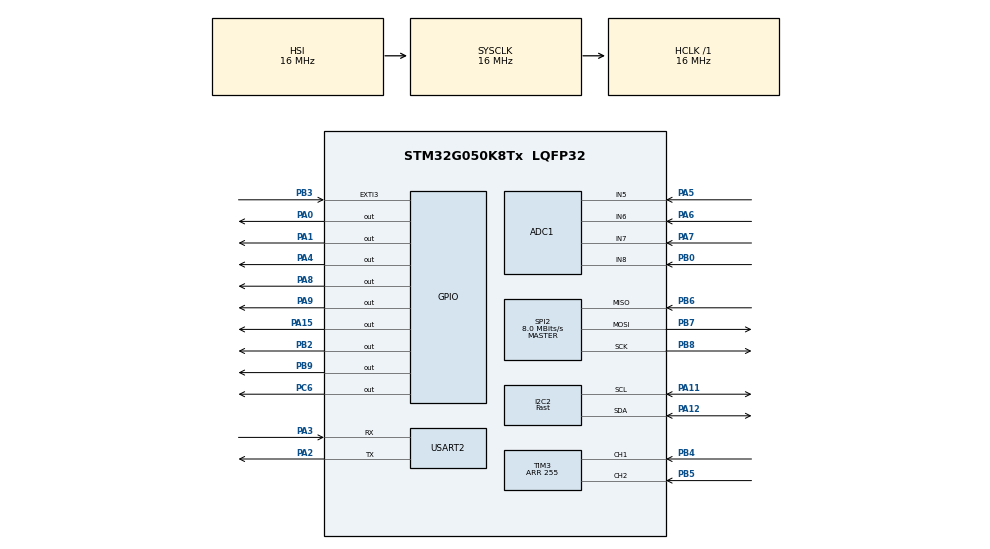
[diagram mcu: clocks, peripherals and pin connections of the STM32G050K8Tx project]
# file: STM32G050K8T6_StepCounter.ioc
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ADC1.Channel-0\#ChannelRegularConversion=ADC_CHANNEL_5
ADC1.Channel-1\#ChannelRegularConversion=ADC_CHANNEL_6
ADC1.Channel-2\#ChannelRegularConversion=ADC_CHANNEL_7
ADC1.Channel-3\#ChannelRegularConversion=ADC_CHANNEL_8
ADC1.ContinuousConvMode=ENABLE
ADC1.EOCSelection=ADC_EOC_SEQ_CONV
ADC1.NbrOfConversion=4
ADC1.NbrOfConversionFlag=1
ADC1.Rank-0\#ChannelRegularConversion=1
ADC1.Rank-1\#ChannelRegularConversion=2
ADC1.Rank-2\#ChannelRegularConversion=3
ADC1.Rank-3\#ChannelRegularConversion=4
ADC1.SamplingTime-0\#ChannelRegularConversion=ADC_SAMPLINGTIME_COMMON_1
ADC1.SamplingTime-1\#ChannelRegularConversion=ADC_SAMPLINGTIME_COMMON_1
ADC1.SamplingTime-2\#ChannelRegularConversion=ADC_SAMPLINGTIME_COMMON_1
ADC1.SamplingTime-3\#ChannelRegularConversion=ADC_SAMPLINGTIME_COMMON_1
ADC1.SelectedChannel=ADC_CHANNEL_5|ADC_CHANNEL_6|ADC_CHANNEL_7|ADC_CHANNEL_8
ADC1.master=1
Dma.ADC1.0.Direction=DMA_PERIPH_TO_MEMORY
Dma.ADC1.0.EventEnable=DISABLE
Dma.ADC1.0.Instance=DMA1_Channel1
Dma.ADC1.0.MemDataAlignment=DMA_MDATAALIGN_HALFWORD
Dma.ADC1.0.MemInc=DMA_MINC_ENABLE
Dma.ADC1.0.Mode=DMA_CIRCULAR
Dma.ADC1.0.PeriphDataAlignment=DMA_PDATAALIGN_HALFWORD
Dma.ADC1.0.PeriphInc=DMA_PINC_DISABLE
Dma.ADC1.0.Polarity=HAL_DMAMUX_REQ_GEN_RISING
Dma.ADC1.0.Priority=DMA_PRIORITY_LOW
Dma.ADC1.0.RequestNumber=1
Dma.ADC1.0.SignalID=NONE
Dma.ADC1.0.SyncEnable=DISABLE
Dma.ADC1.0.SyncPolarity=HAL_DMAMUX_SYNC_NO_EVENT
Dma.ADC1.0.SyncRequestNumber=1
Dma.ADC1.0.SyncSignalID=NONE
Dma.Request0=ADC1
I2C2.I2C_Speed_Mode=I2C_Fast
I2C2.Timing=0x00300617
Mcu.Family=STM32G0
Mcu.Name=STM32G050K8Tx
Mcu.Package=LQFP32
NVIC.DMA1_Channel1_IRQn=true\:0\:0\:false\:false\:true\:false\:true\:true
NVIC.TIM3_IRQn=true\:0\:0\:false\:false\:true\:true\:true\:true
PA0.Signal=GPIO_Output
PA1.Signal=GPIO_Output
PA11\ [PA9].Mode=I2C
PA11\ [PA9].Signal=I2C2_SCL
PA12\ [PA10].Mode=I2C
PA12\ [PA10].Signal=I2C2_SDA
PA13.Mode=Serial_Wire
PA13.Signal=SYS_SWDIO
PA14-BOOT0.Mode=Serial_Wire
PA14-BOOT0.Signal=SYS_SWCLK
PA15.Signal=GPIO_Output
PA2.Mode=Asynchronous
PA2.Signal=USART2_TX
PA3.Mode=Asynchronous
PA3.Signal=USART2_RX
PA4.Signal=GPIO_Output
PA5.Mode=IN5
PA5.Signal=ADC1_IN5
PA6.Mode=IN6
PA6.Signal=ADC1_IN6
PA7.Mode=IN7
PA7.Signal=ADC1_IN7
PA8.Signal=GPIO_Output
PA9.Signal=GPIO_Output
PB0.Mode=IN8
PB0.Signal=ADC1_IN8
PB2.Signal=GPIO_Output
PB3.Signal=GPXTI3
PB4.Signal=S_TIM3_CH1
PB5.Signal=S_TIM3_CH2
PB6.Mode=Full_Duplex_Master
PB6.Signal=SPI2_MISO
PB7.Mode=Full_Duplex_Master
PB7.Signal=SPI2_MOSI
PB8.Mode=Full_Duplex_Master
PB8.Signal=SPI2_SCK
PB9.Signal=GPIO_Output
PC6.Signal=GPIO_Output
ProjectManager.HeapSize=0x200
ProjectManager.StackSize=0x400
ProjectManager.TargetToolchain=STM32CubeIDE
RCC.AHBFreq_Value=16000000
RCC.CortexFreq_Value=16000000
RCC.EXTERNAL_CLOCK_VALUE=48000
RCC.HCLKFreq_Value=16000000
RCC.HSE_VALUE=8000000
RCC.HSI_VALUE=16000000
RCC.LSE_VALUE=32768
RCC.SYSCLKFreq_VALUE=16000000
RCC.VCOOutputFreq_Value=128000000
SH.S_TIM3_CH1.0=TIM3_CH1,Encoder_Interface
SH.S_TIM3_CH2.0=TIM3_CH2,Encoder_Interface
SPI2.CalculateBaudRate=8.0 MBits/s
SPI2.Direction=SPI_DIRECTION_2LINES
SPI2.Mode=SPI_MODE_MASTER
SPI2.VirtualType=VM_MASTER
TIM3.EncoderMode=TIM_ENCODERMODE_TI12
TIM3.IC1Polarity=TIM_ICPOLARITY_FALLING
TIM3.IC2Polarity=TIM_ICPOLARITY_FALLING
TIM3.Period=255
USART2.VirtualMode-Asynchronous=VM_ASYNC
VP_SYS_VS_DBSignals.Mode=DisableDeadBatterySignals
board=custom

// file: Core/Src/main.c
/* USER CODE BEGIN Header */
/**
  ******************************************************************************
  * @file           : main.c
  * @brief          : Main program body
  ******************************************************************************
  * @attention
  *
  * Copyright (c) 2025 STMicroelectronics.
  * All rights reserved.
  *
  * This software is licensed under terms that can be found in the LICENSE file
  * in the root directory of this software component.
  * If no LICENSE file comes with this software, it is provided AS-IS.
  *
  ******************************************************************************
  */
/* USER CODE END Header */
#include "main.h"

/* USER CODE BEGIN PD */
#define ADC_NUM_CONVERSIONS 3
#define ADC_RAW_TO_VOLTAGE 1.0071108127
#define VOLTAGE_INPUT 3.3
#define RESOLUTION 4096
#define g_BIAS_XY 1.65
#define g_BIAS_Z 1.8
#define SENSITIVITY 300
#define SELF_TEST_GPIO 4
#define SELF_TEST_MIN {-150, 150, 150}
#define SELF_TEST_TYP {-325, 325, 550}
#define SELF_TEST_MAX {-600, 600, 1000}
#define NUM_SAMPLES 100
#define G_TOLERANCE 0.05

float g_Bias[3] = {g_BIAS_XY, g_BIAS_XY, g_BIAS_Z};

/* USER CODE END PD */

ADC_HandleTypeDef hadc1;
DMA_HandleTypeDef hdma_adc1;

I2C_HandleTypeDef hi2c2;

SPI_HandleTypeDef hspi2;

TIM_HandleTypeDef htim3;

UART_HandleTypeDef huart2;

/* USER CODE BEGIN PV */
volatile uint16_t adcData[ADC_NUM_CONVERSIONS];
volatile float adxlVoltage[ADC_NUM_CONVERSIONS];
volatile float gData[ADC_NUM_CONVERSIONS];
volatile float VOLTAGE_ST[ADC_NUM_CONVERSIONS];
volatile float VOLTAGE_BUFFER_BEFORE[ADC_NUM_CONVERSIONS];
volatile float VOLTAGE_BUFFER_AFTER[ADC_NUM_CONVERSIONS];
const uint16_t SelfTestMin[ADC_NUM_CONVERSIONS] = SELF_TEST_MIN;
const uint16_t SelfTestTyp[ADC_NUM_CONVERSIONS] = SELF_TEST_TYP;
const uint16_t SelfTestMax[ADC_NUM_CONVERSIONS] = SELF_TEST_MAX;
volatile uint8_t CONVERSION = 0;
uint8_t pass = 0;
volatile uint8_t SELF_TEST = 0;
/* USER CODE END PV */

void SystemClock_Config(void);
static void MX_GPIO_Init(void);
static void MX_DMA_Init(void);
static void MX_ADC1_Init(void);
static void MX_I2C2_Init(void);
static void MX_SPI2_Init(void);
static void MX_TIM3_Init(void);
static void MX_USART2_UART_Init(void);

/* USER CODE BEGIN 0 */
void HAL_ADC_ConvCpltCallback(ADC_HandleTypeDef *hadc){
	CONVERSION = 1;
}

void Calculate_g(void){
	for(int i = 0; i < ADC_NUM_CONVERSIONS; i++){
	  adxlVoltage[i] = adcData[i] * VOLTAGE_INPUT/RESOLUTION * 1000;
	  gData[i] = (adxlVoltage[i] - g_Bias[i])/SENSITIVITY;
	}
}

void ToggleLED_ST(void){
	 HAL_GPIO_TogglePin(GPIOC, GPIO_PIN_6);
	 SELF_TEST = !SELF_TEST;                   // Toggle self-test flag
	 HAL_Delay(500);
}

void Perform_Self_Test(void){
	self_test_finished = false;
	//screen1();
	ToggleLED_ST();

	if(SELF_TEST) {
	  for(int i = 0; i < ADC_NUM_CONVERSIONS; i++) {
		  VOLTAGE_BUFFER_AFTER[i] = adxlVoltage[i];
	//	          printf("Axis , VOLTAGE_BUFFER_AFTER = %.2f\n", i, VOLTAGE_BUFFER_AFTER[i]);
	  }

	  for(int i = 0; i < ADC_NUM_CONVERSIONS; i++) {
		  VOLTAGE_ST[i] = VOLTAGE_BUFFER_AFTER[i] - VOLTAGE_BUFFER_BEFORE[i];
	//	          printf("Axis %d: VOLTAGE_ST = %.2f\n", i, VOLTAGE_ST[i]);

		  if(VOLTAGE_ST[i] >= SelfTestMin[i] && VOLTAGE_ST[i] <= SelfTestMax[i]) {
			  printf("Self-test PASSED");
			  self_test_finished = true;
		  }
		  else {
			  printf("Self-test FAILED");
		  }
	  }
	}

	//	(VOLTAGE_BUFFER_BEFORE) is updated when the self-test is off.
	//	Once you turn self-test on, you use the previously stored baseline to compare with the new measurement.

	else {
	  for(int i = 0; i < ADC_NUM_CONVERSIONS; i++) {
		  VOLTAGE_BUFFER_BEFORE[i] = adxlVoltage[i];
	  }
	}
}

// Keeps collecting samples every conversion
void Collect_Samples_mV(float *samples, int axis) {
	for(int i = 0; i < NUM_SAMPLES; i++) {
		while(!CONVERSION); //while ADC complete callback has not achieved
		samples[i] = adxlVoltage[axis]; //collect data before conversion completed
		CONVERSION = 0;
	}
}

// Get average data of mV
float Calculate_Average_mV(float *samples) {
	float sum = 0;
	for(int i = 0; i < NUM_SAMPLES; i++) {
		sum += samples[i];
	}
	return sum /NUM_SAMPLES;
}

// Keeps adjusting bias until g is +-1g
void Adjust_Bias_And_Recalculate(int axis) {
	bool pass = false;
	float g;

	while(!pass){
		adxlVoltage[axis] = adcData[axis] * VOLTAGE_INPUT/RESOLUTION * 1000;
		g = (adxlVoltage[axis] - g_Bias[axis])/SENSITIVITY;

		// if not +-0.05 from +-1g, extract g_Bias
		if(g < 0.95 || g > 1.05) {
			g_Bias[axis] = adxlVoltage[axis] - SENSITIVITY;
		}
		else if(g < -1.05 || g > -0.95) {
			g_Bias[axis] = adxlVoltage[axis] + SENSITIVITY;
		}

		// adjust g according to g_Bias
		gData[axis] = (adxlVoltage[axis] - g_Bias[axis]) / SENSITIVITY;
		g = gData[axis];
		printf("Calculating...");

		if(0.95 <= g && g <= 1.05 || -1.05 <= g && g <= -0.95) {
			pass = true;
		}
	}
	if (pass) {
		printf("Calibration PASSED");
	}
}

void Calibrate_ADXL(int axis) {
	calibrate_finished = false;
//	screen4();
//	screen5();
	float samples[NUM_SAMPLES];

	for(int i = 0; i < ADC_NUM_CONVERSIONS; i++) {
		Collect_Samples_mV(samples, i);
		g_Bias[i] = Calculate_Average_mV(samples);
		Adjust_Bias_And_Recalculate(i);
	}
}

//void SimulateADCData(void); //Simulate ADC data for testing

/* USER CODE END 0 */

int main(void)
{

  /* MCU Configuration--------------------------------------------------------*/

  /* Reset of all peripherals, Initializes the Flash interface and the Systick. */
  HAL_Init();

  /* Configure the system clock */
  SystemClock_Config();

  /* Initialize all configured peripherals */
  MX_GPIO_Init();
  MX_DMA_Init();
  MX_ADC1_Init();
  MX_I2C2_Init();
  MX_SPI2_Init();
  MX_TIM3_Init();
  MX_USART2_UART_Init();
  /* USER CODE BEGIN 2 */
  HAL_ADC_Start_DMA(&hadc1, (uint32_t *) adcData, ADC_NUM_CONVERSIONS);
  HAL_TIM_Base_Start(&htim2);

  void HAL_ADC_ConvCpltCallback(ADC_HandleTypeDef *hadc);
  Calibrate_ADXL(ADC_NUM_CONVERSIONS);

  /* USER CODE END 2 */

  /* Infinite loop */
  while (1)
  {

    /* USER CODE BEGIN 3 */
//	  SimulateADCData();
	  if(CONVERSION) { 			// if receive conversion value
		  Calculate_g();
	  }
	  Perform_Self_Test();

	  Calibrate_ADXL();

//	  hi test2
  }
  /* USER CODE END 3 */
}

void SystemClock_Config(void)
{
  RCC_OscInitTypeDef RCC_OscInitStruct = {0};
  RCC_ClkInitTypeDef RCC_ClkInitStruct = {0};

  /** Configure the main internal regulator output voltage
  */
  HAL_PWREx_ControlVoltageScaling(PWR_REGULATOR_VOLTAGE_SCALE1);

  /** Initializes the RCC Oscillators according to the specified parameters
  * in the RCC_OscInitTypeDef structure.
  */
  RCC_OscInitStruct.OscillatorType = RCC_OSCILLATORTYPE_HSI;
  RCC_OscInitStruct.HSIState = RCC_HSI_ON;
  RCC_OscInitStruct.HSIDiv = RCC_HSI_DIV1;
  RCC_OscInitStruct.HSICalibrationValue = RCC_HSICALIBRATION_DEFAULT;
  RCC_OscInitStruct.PLL.PLLState = RCC_PLL_NONE;
  if (HAL_RCC_OscConfig(&RCC_OscInitStruct) != HAL_OK)
  {
    Error_Handler();
  }

  /** Initializes the CPU, AHB and APB buses clocks
  */
  RCC_ClkInitStruct.ClockType = RCC_CLOCKTYPE_HCLK|RCC_CLOCKTYPE_SYSCLK
                              |RCC_CLOCKTYPE_PCLK1;
  RCC_ClkInitStruct.SYSCLKSource = RCC_SYSCLKSOURCE_HSI;
  RCC_ClkInitStruct.AHBCLKDivider = RCC_SYSCLK_DIV1;
  RCC_ClkInitStruct.APB1CLKDivider = RCC_HCLK_DIV1;

  if (HAL_RCC_ClockConfig(&RCC_ClkInitStruct, FLASH_LATENCY_0) != HAL_OK)
  {
    Error_Handler();
  }
}

static void MX_ADC1_Init(void)
{

  ADC_ChannelConfTypeDef sConfig = {0};

  /** Configure the global features of the ADC (Clock, Resolution, Data Alignment and number of conversion)
  */
  hadc1.Instance = ADC1;
  hadc1.Init.ClockPrescaler = ADC_CLOCK_SYNC_PCLK_DIV2;
  hadc1.Init.Resolution = ADC_RESOLUTION_12B;
  hadc1.Init.DataAlign = ADC_DATAALIGN_RIGHT;
  hadc1.Init.ScanConvMode = ADC_SCAN_ENABLE;
  hadc1.Init.EOCSelection = ADC_EOC_SEQ_CONV;
  hadc1.Init.LowPowerAutoWait = DISABLE;
  hadc1.Init.LowPowerAutoPowerOff = DISABLE;
  hadc1.Init.ContinuousConvMode = ENABLE;
  hadc1.Init.NbrOfConversion = 3;
  hadc1.Init.ExternalTrigConv = ADC_SOFTWARE_START;
  hadc1.Init.ExternalTrigConvEdge = ADC_EXTERNALTRIGCONVEDGE_NONE;
  hadc1.Init.DMAContinuousRequests = DISABLE;
  hadc1.Init.Overrun = ADC_OVR_DATA_PRESERVED;
  hadc1.Init.SamplingTimeCommon1 = ADC_SAMPLETIME_1CYCLE_5;
  hadc1.Init.SamplingTimeCommon2 = ADC_SAMPLETIME_1CYCLE_5;
  hadc1.Init.OversamplingMode = DISABLE;
  hadc1.Init.TriggerFrequencyMode = ADC_TRIGGER_FREQ_HIGH;
  if (HAL_ADC_Init(&hadc1) != HAL_OK)
  {
    Error_Handler();
  }

  /** Configure Regular Channel
  */
  sConfig.Channel = ADC_CHANNEL_5;
  sConfig.Rank = ADC_REGULAR_RANK_1;
  sConfig.SamplingTime = ADC_SAMPLINGTIME_COMMON_1;
  if (HAL_ADC_ConfigChannel(&hadc1, &sConfig) != HAL_OK)
  {
    Error_Handler();
  }

  /** Configure Regular Channel
  */
  sConfig.Channel = ADC_CHANNEL_6;
  sConfig.Rank = ADC_REGULAR_RANK_2;
  if (HAL_ADC_ConfigChannel(&hadc1, &sConfig) != HAL_OK)
  {
    Error_Handler();
  }

  /** Configure Regular Channel
  */
  sConfig.Channel = ADC_CHANNEL_7;
  sConfig.Rank = ADC_REGULAR_RANK_3;
  if (HAL_ADC_ConfigChannel(&hadc1, &sConfig) != HAL_OK)
  {
    Error_Handler();
  }

}

static void MX_I2C2_Init(void)
{

  hi2c2.Instance = I2C2;
  hi2c2.Init.Timing = 0x00300617;
  hi2c2.Init.OwnAddress1 = 0;
  hi2c2.Init.AddressingMode = I2C_ADDRESSINGMODE_7BIT;
  hi2c2.Init.DualAddressMode = I2C_DUALADDRESS_DISABLE;
  hi2c2.Init.OwnAddress2 = 0;
  hi2c2.Init.OwnAddress2Masks = I2C_OA2_NOMASK;
  hi2c2.Init.GeneralCallMode = I2C_GENERALCALL_DISABLE;
  hi2c2.Init.NoStretchMode = I2C_NOSTRETCH_DISABLE;
  if (HAL_I2C_Init(&hi2c2) != HAL_OK)
  {
    Error_Handler();
  }

  /** Configure Analogue filter
  */
  if (HAL_I2CEx_ConfigAnalogFilter(&hi2c2, I2C_ANALOGFILTER_ENABLE) != HAL_OK)
  {
    Error_Handler();
  }

  /** Configure Digital filter
  */
  if (HAL_I2CEx_ConfigDigitalFilter(&hi2c2, 0) != HAL_OK)
  {
    Error_Handler();
  }

}

static void MX_SPI2_Init(void)
{

  /* SPI2 parameter configuration*/
  hspi2.Instance = SPI2;
  hspi2.Init.Mode = SPI_MODE_MASTER;
  hspi2.Init.Direction = SPI_DIRECTION_2LINES;
  hspi2.Init.DataSize = SPI_DATASIZE_8BIT;
  hspi2.Init.CLKPolarity = SPI_POLARITY_LOW;
  hspi2.Init.CLKPhase = SPI_PHASE_1EDGE;
  hspi2.Init.NSS = SPI_NSS_SOFT;
  hspi2.Init.BaudRatePrescaler = SPI_BAUDRATEPRESCALER_2;
  hspi2.Init.FirstBit = SPI_FIRSTBIT_MSB;
  hspi2.Init.TIMode = SPI_TIMODE_DISABLE;
  hspi2.Init.CRCCalculation = SPI_CRCCALCULATION_DISABLE;
  hspi2.Init.CRCPolynomial = 7;
  hspi2.Init.CRCLength = SPI_CRC_LENGTH_DATASIZE;
  hspi2.Init.NSSPMode = SPI_NSS_PULSE_ENABLE;
  if (HAL_SPI_Init(&hspi2) != HAL_OK)
  {
    Error_Handler();
  }

}

static void MX_TIM3_Init(void)
{

  TIM_Encoder_InitTypeDef sConfig = {0};
  TIM_MasterConfigTypeDef sMasterConfig = {0};

  htim3.Instance = TIM3;
  htim3.Init.Prescaler = 0;
  htim3.Init.CounterMode = TIM_COUNTERMODE_UP;
  htim3.Init.Period = 255;
  htim3.Init.ClockDivision = TIM_CLOCKDIVISION_DIV1;
  htim3.Init.AutoReloadPreload = TIM_AUTORELOAD_PRELOAD_DISABLE;
  sConfig.EncoderMode = TIM_ENCODERMODE_TI12;
  sConfig.IC1Polarity = TIM_ICPOLARITY_FALLING;
  sConfig.IC1Selection = TIM_ICSELECTION_DIRECTTI;
  sConfig.IC1Prescaler = TIM_ICPSC_DIV1;
  sConfig.IC1Filter = 0;
  sConfig.IC2Polarity = TIM_ICPOLARITY_FALLING;
  sConfig.IC2Selection = TIM_ICSELECTION_DIRECTTI;
  sConfig.IC2Prescaler = TIM_ICPSC_DIV1;
  sConfig.IC2Filter = 0;
  if (HAL_TIM_Encoder_Init(&htim3, &sConfig) != HAL_OK)
  {
    Error_Handler();
  }
  sMasterConfig.MasterOutputTrigger = TIM_TRGO_RESET;
  sMasterConfig.MasterSlaveMode = TIM_MASTERSLAVEMODE_DISABLE;
  if (HAL_TIMEx_MasterConfigSynchronization(&htim3, &sMasterConfig) != HAL_OK)
  {
    Error_Handler();
  }

}

static void MX_USART2_UART_Init(void)
{

  huart2.Instance = USART2;
  huart2.Init.BaudRate = 115200;
  huart2.Init.WordLength = UART_WORDLENGTH_8B;
  huart2.Init.StopBits = UART_STOPBITS_1;
  huart2.Init.Parity = UART_PARITY_NONE;
  huart2.Init.Mode = UART_MODE_TX_RX;
  huart2.Init.HwFlowCtl = UART_HWCONTROL_NONE;
  huart2.Init.OverSampling = UART_OVERSAMPLING_16;
  huart2.Init.OneBitSampling = UART_ONE_BIT_SAMPLE_DISABLE;
  huart2.Init.ClockPrescaler = UART_PRESCALER_DIV1;
  huart2.AdvancedInit.AdvFeatureInit = UART_ADVFEATURE_NO_INIT;
  if (HAL_UART_Init(&huart2) != HAL_OK)
  {
    Error_Handler();
  }

}

static void MX_DMA_Init(void)
{

  /* DMA controller clock enable */
  __HAL_RCC_DMA1_CLK_ENABLE();

  /* DMA interrupt init */
  /* DMA1_Channel1_IRQn interrupt configuration */
  HAL_NVIC_SetPriority(DMA1_Channel1_IRQn, 0, 0);
  HAL_NVIC_EnableIRQ(DMA1_Channel1_IRQn);

}

static void MX_GPIO_Init(void)
{
  GPIO_InitTypeDef GPIO_InitStruct = {0};

  /* GPIO Ports Clock Enable */
  __HAL_RCC_GPIOB_CLK_ENABLE();
  __HAL_RCC_GPIOA_CLK_ENABLE();
  __HAL_RCC_GPIOC_CLK_ENABLE();

  /*Configure GPIO pin Output Level */
  HAL_GPIO_WritePin(GPIOB, GPIO_PIN_9|GPIO_PIN_2, GPIO_PIN_RESET);

  /*Configure GPIO pin Output Level */
  HAL_GPIO_WritePin(GPIOA, GPIO_PIN_0|GPIO_PIN_1|GPIO_PIN_4|GPIO_PIN_8
                          |GPIO_PIN_9|GPIO_PIN_10|GPIO_PIN_15, GPIO_PIN_RESET);

  /*Configure GPIO pin Output Level */
  HAL_GPIO_WritePin(GPIOC, GPIO_PIN_6, GPIO_PIN_RESET);

  /*Configure GPIO pins : PB9 PB2 */
  GPIO_InitStruct.Pin = GPIO_PIN_9|GPIO_PIN_2;
  GPIO_InitStruct.Mode = GPIO_MODE_OUTPUT_PP;
  GPIO_InitStruct.Pull = GPIO_NOPULL;
  GPIO_InitStruct.Speed = GPIO_SPEED_FREQ_LOW;
  HAL_GPIO_Init(GPIOB, &GPIO_InitStruct);

  /*Configure GPIO pins : PA0 PA1 PA4 PA8
                           PA9 PA10 PA15 */
  GPIO_InitStruct.Pin = GPIO_PIN_0|GPIO_PIN_1|GPIO_PIN_4|GPIO_PIN_8
                          |GPIO_PIN_9|GPIO_PIN_10|GPIO_PIN_15;
  GPIO_InitStruct.Mode = GPIO_MODE_OUTPUT_PP;
  GPIO_InitStruct.Pull = GPIO_NOPULL;
  GPIO_InitStruct.Speed = GPIO_SPEED_FREQ_LOW;
  HAL_GPIO_Init(GPIOA, &GPIO_InitStruct);

  /*Configure GPIO pin : PC6 */
  GPIO_InitStruct.Pin = GPIO_PIN_6;
  GPIO_InitStruct.Mode = GPIO_MODE_OUTPUT_PP;
  GPIO_InitStruct.Pull = GPIO_NOPULL;
  GPIO_InitStruct.Speed = GPIO_SPEED_FREQ_LOW;
  HAL_GPIO_Init(GPIOC, &GPIO_InitStruct);

  /*Configure GPIO pin : PB3 */
  GPIO_InitStruct.Pin = GPIO_PIN_3;
  GPIO_InitStruct.Mode = GPIO_MODE_IT_RISING;
  GPIO_InitStruct.Pull = GPIO_NOPULL;
  HAL_GPIO_Init(GPIOB, &GPIO_InitStruct);

}

void Error_Handler(void)
{
  __disable_irq();
  while (1)
  {
  }
}
